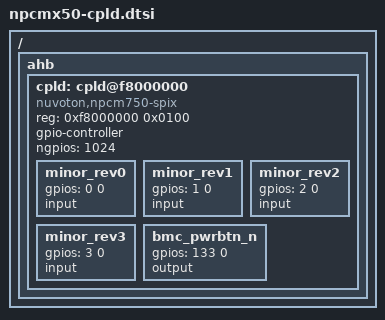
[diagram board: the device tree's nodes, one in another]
/*
 * The code contained herein is licensed under the GNU General Public
 * License. You may obtain a copy of the GNU General Public License
 * Version 2 or later at the following locations:
 *
 * http://www.opensource.org/licenses/gpl-license.html
 * http://www.gnu.org/copyleft/gpl.html
 */


/ {     
	ahb {
        	cpld: cpld@f8000000 {
        		compatible = "nuvoton,npcm750-spix";
        		reg = <0xf8000000 0x0100>;
                        gpio-controller;
                        #gpio-cells = <2>;
                        ngpios = <1024>;

                        minor_rev0 {
                            gpios = <0 0>;
                            input;
                        };
                        minor_rev1 {
                            gpios = <1 0>;
                            input;
                        };
                        minor_rev2 {
                            gpios = <2 0>;
                            input;
                        };
                        minor_rev3 {
                            gpios = <3 0>;
                            input;
                        };
                        bmc_pwrbtn_n{
                            gpios = <133 0>;
                            output;
                        };

#if 0
			gpio-line-names = "MINOR_REV_0", "MINOR_REV_1", "MINOR_REV_2", "MINOR_REV_3", "MAJOR_REV_0", "MAJOR_REV_1", "MAJOR_REV_2", "MAJOR_REV_3",
				     "MAINT_REV_0", "MAINT_REV_1", "MAINT_REV_2", "MAINT_REV_3", "", "", "", "",
				     "", "", "", "", "", "", "", "",
				     "", "", "", "", "", "", "", "",
				     "", "", "", "", "", "", "", "",
				     "", "", "", "", "", "", "", "",
				     "", "", "", "", "", "", "", "",
				     "", "", "", "", "", "", "", "",
				     "", "", "", "", "", "", "", "",
				     "", "", "", "", "", "", "", "",
				     "", "", "", "", "", "", "", "",
				     "", "", "", "", "", "", "", "",
				     "", "", "", "", "", "", "", "",
				     "", "", "", "", "", "", "", "",
				     "", "", "", "", "", "", "", "",
				     "", "", "", "", "", "", "", "",
				     "", "", "", "", "", "", "", "",
				     "", "", "", "", "", "", "", "",
				     "", "", "", "", "", "", "", "",
				     "", "", "", "", "", "", "", "",
				     "", "", "", "", "", "", "", "",
				     "", "", "", "", "", "", "", "",
				     "", "", "", "", "", "", "", "",
				     "", "", "", "", "", "", "", "",
				     "", "", "", "", "", "", "", "",
				     "", "", "", "", "", "", "", "",
				     "", "", "", "", "", "", "", "",
				     "", "", "", "", "", "", "", "",
				     "", "", "", "", "", "", "", "",
				     "", "", "", "", "", "", "", "",
				     "", "", "", "", "", "", "", "",
				     "", "", "", "", "", "", "", "",
				     "", "", "", "", "", "", "", "",
				     "", "", "", "", "", "", "", "",
				     "", "", "", "", "", "", "", "",
				     "", "", "", "", "", "", "", "",
				     "", "", "", "", "", "", "", "",
				     "", "", "", "", "", "", "", "",
				     "", "", "", "", "", "", "", "",
				     "", "", "", "", "", "", "", "",
				     "", "", "", "", "", "", "", "",
				     "", "", "", "", "", "", "", "",
				     "", "", "", "", "", "", "", "",
				     "", "", "", "", "", "", "", "",
				     "", "", "", "", "", "", "", "",
				     "", "", "", "", "", "", "", "",
				     "", "", "", "", "", "", "", "",
				     "", "", "", "", "", "", "", "",
				     "", "", "", "", "", "", "", "",
				     "", "", "", "", "", "", "", "",
				     "", "", "", "", "", "", "", "",
				     "", "", "", "", "", "", "", "",
				     "", "", "", "", "", "", "", "",
				     "", "", "", "", "", "", "", "",
				     "", "", "", "", "", "", "", "",
				     "", "", "", "", "", "", "", "",
				     "", "", "", "", "", "", "", "",
				     "", "", "", "", "", "", "", "",
				     "", "", "", "", "", "", "", "",
				     "", "", "", "", "", "", "", "",
				     "", "", "", "", "", "", "", "",
				     "", "", "", "", "", "", "", "",
				     "", "", "", "", "", "", "", "",
				     "", "", "", "", "", "", "", "",
				     "", "", "", "", "", "", "", "",
				     "", "", "", "", "", "", "", "",
				     "", "", "", "", "", "", "", "",
				     "", "", "", "", "", "", "", "",
				     "", "", "", "", "", "", "", "",
				     "", "", "", "", "", "", "", "",
				     "", "", "", "", "", "", "", "",
				     "", "", "", "", "", "", "", "",
				     "", "", "", "", "", "", "", "",
				     "", "", "", "", "", "", "", "",
				     "", "", "", "", "", "", "", "",
				     "", "", "", "", "", "", "", "",
				     "", "", "", "", "", "", "", "",
				     "", "", "", "", "", "", "", "",
				     "", "", "", "", "", "", "", "",
				     "", "", "", "", "", "", "", "",
				     "", "", "", "", "", "", "", "",
				     "", "", "", "", "", "", "", "",
				     "", "", "", "", "", "", "", "",
				     "", "", "", "", "", "", "", "",
				     "", "", "", "", "", "", "", "",
				     "", "", "", "", "", "", "", "",
				     "", "", "", "", "", "", "", "",
				     "", "", "", "", "", "", "", "",
				     "", "", "", "", "", "", "", "",
				     "", "", "", "", "", "", "", "",
				     "", "", "", "", "", "", "", "",
				     "", "", "", "", "", "", "", "",
				     "", "", "", "", "", "", "", "",
				     "", "", "", "", "", "", "", "",
				     "", "", "", "", "", "", "", "",
				     "", "", "", "", "", "", "", "",
				     "", "", "", "", "", "", "", "",
				     "", "", "", "", "", "", "", "",
				     "", "", "", "", "", "", "", "",
				     "", "", "", "", "", "", "", "",
				     "", "", "", "", "", "", "", "",
				     "", "", "", "", "", "", "", "",
				     "", "", "", "", "", "", "", "",
				     "", "", "", "", "", "", "", "",
				     "", "", "", "", "", "", "", "",
				     "", "", "", "", "", "", "", "",
				     "", "", "", "", "", "", "", "",
				     "", "", "", "", "", "", "", "",
				     "", "", "", "", "", "", "", "",
				     "", "", "", "", "", "", "", "",
				     "", "", "", "", "", "", "", "",
				     "", "", "", "", "", "", "", "",
				     "", "", "", "", "", "", "", "",
				     "", "", "", "", "", "", "", "",
				     "", "", "", "", "", "", "", "",
				     "", "", "", "", "", "", "", "",
				     "", "", "", "", "", "", "", "",
				     "", "", "", "", "", "", "", "",
				     "", "", "", "", "", "", "", "",
				     "", "", "", "", "", "", "", "",
				     "", "", "", "", "", "", "", "",
				     "", "", "", "", "", "", "", "",
				     "", "", "", "", "", "", "", "",
				     "", "", "", "", "", "", "", "",
				     "", "", "", "", "", "", "", "",
				     "", "", "", "", "", "", "", "",
				     "", "", "", "", "", "", "", "",
				     "", "", "", "", "", "", "", "";
#endif


        	};
        };
};
